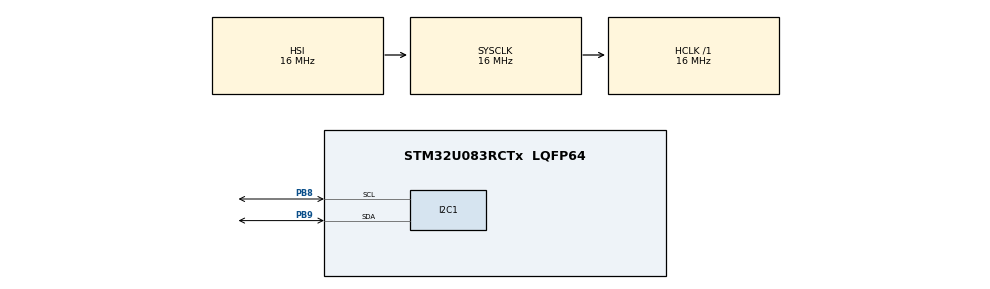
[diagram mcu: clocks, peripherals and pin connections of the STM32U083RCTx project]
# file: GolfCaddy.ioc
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I2C1.Timing=0x00303D5B
Mcu.Family=STM32U0
Mcu.Name=STM32U083RCTx
Mcu.Package=LQFP64
NUCLEO-U083RC.BUTTON=1
NUCLEO-U083RC.LD4=true
NUCLEO-U083RC.VCP=true
NVIC.EXTI4_15_IRQn=true\:0\:0\:false\:false\:true\:false\:true\:true
NVIC.PriorityGroup=NVIC_PRIORITYGROUP_2
PA13\ (SWDIO).GPIO_Label=SWDIO
PA13\ (SWDIO).Signal=DEBUG_JTMS-SWDIO
PA14\ (SWCLK).GPIO_Label=SWCLK
PA14\ (SWCLK).Signal=DEBUG_JTCK-SWCLK
PA2.Signal=USART2_TX
PA3.Signal=USART2_RX
PB8.Mode=I2C
PB8.Signal=I2C1_SCL
PB9.Mode=I2C
PB9.Signal=I2C1_SDA
PC14-OSC32_IN.GPIO_Label=OSC32_IN
PC14-OSC32_IN.Signal=RCC_OSC32_IN
PC15-OSC32_OUT.GPIO_Label=OSC32_OUT
PC15-OSC32_OUT.Signal=RCC_OSC32_OUT
PF0-OSC_IN.GPIO_Label=OSC_IN
PF0-OSC_IN.Signal=RCC_OSC_IN
PF1-OSC_OUT.GPIO_Label=OSC_OUT
PF1-OSC_OUT.Signal=RCC_OSC_OUT
ProjectManager.HeapSize=0x200
ProjectManager.StackSize=0x400
ProjectManager.TargetToolchain=STM32CubeIDE
RCC.AHBFreq_Value=16000000
RCC.CortexFreq_Value=16000000
RCC.HCLKFreq_Value=16000000
RCC.HSE_VALUE=4000000
RCC.HSI48_VALUE=48000000
RCC.HSI_VALUE=16000000
RCC.LSE_VALUE=32768
RCC.MSI_VALUE=4000000
RCC.SYSCLKFreq_VALUE=16000000
RCC.VCOOutputFreq_Value=64000000
VP_NUCLEO-U083RC_VS_BSP_COMMON.Mode=COMMON
VP_PWR_VS_SECSignals.Mode=Security/Privilege
board=NUCLEO-U083RC

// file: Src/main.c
/* USER CODE BEGIN Header */
/**
  ******************************************************************************
  * @file           : main.c
  * @brief          : Main program body
  ******************************************************************************
  * @attention
  *
  * Copyright (c) 2026 STMicroelectronics.
  * All rights reserved.
  *
  * This software is licensed under terms that can be found in the LICENSE file
  * in the root directory of this software component.
  * If no LICENSE file comes with this software, it is provided AS-IS.
  *
  ******************************************************************************
  */
/* USER CODE END Header */
#include "main.h"
#include "i2c.h"
#include "gpio.h"

/* USER CODE BEGIN Includes */
#include "app.h"
/* USER CODE END Includes */

COM_InitTypeDef BspCOMInit;

void SystemClock_Config(void);

int main(void)
{

  /* MCU Configuration--------------------------------------------------------*/

  /* Reset of all peripherals, Initializes the Flash interface and the Systick. */
  HAL_Init();

  /* Configure the system clock */
  SystemClock_Config();

  /* Initialize all configured peripherals */
  MX_GPIO_Init();
  MX_I2C1_Init();
  /* USER CODE BEGIN 2 */
  App_Init();
  /* USER CODE END 2 */

  /* Initialize leds */
  BSP_LED_Init(LED_GREEN);

  /* Initialize USER push-button, will be used to trigger an interrupt each time it's pressed.*/
  BSP_PB_Init(BUTTON_USER, BUTTON_MODE_EXTI);

  /* Initialize COM1 port (115200, 8 bits (7-bit data + 1 stop bit), no parity */
  BspCOMInit.BaudRate   = 115200;
  BspCOMInit.WordLength = COM_WORDLENGTH_8B;
  BspCOMInit.StopBits   = COM_STOPBITS_1;
  BspCOMInit.Parity     = COM_PARITY_NONE;
  BspCOMInit.HwFlowCtl  = COM_HWCONTROL_NONE;
  if (BSP_COM_Init(COM1, &BspCOMInit) != BSP_ERROR_NONE)
  {
    Error_Handler();
  }

  /* Infinite loop */
  /* USER CODE BEGIN WHILE */
  while (1)
  {
	App_Run(HAL_GetTick());
    /* USER CODE END WHILE */

  }
}

void SystemClock_Config(void)
{
  RCC_OscInitTypeDef RCC_OscInitStruct = {0};
  RCC_ClkInitTypeDef RCC_ClkInitStruct = {0};

  /** Configure the main internal regulator output voltage
  */
  HAL_PWREx_ControlVoltageScaling(PWR_REGULATOR_VOLTAGE_SCALE2);

  /** Initializes the RCC Oscillators according to the specified parameters
  * in the RCC_OscInitTypeDef structure.
  */
  RCC_OscInitStruct.OscillatorType = RCC_OSCILLATORTYPE_HSI;
  RCC_OscInitStruct.HSIState = RCC_HSI_ON;
  RCC_OscInitStruct.HSICalibrationValue = RCC_HSICALIBRATION_DEFAULT;
  RCC_OscInitStruct.PLL.PLLState = RCC_PLL_NONE;
  if (HAL_RCC_OscConfig(&RCC_OscInitStruct) != HAL_OK)
  {
    Error_Handler();
  }

  /** Initializes the CPU, AHB and APB buses clocks
  */
  RCC_ClkInitStruct.ClockType = RCC_CLOCKTYPE_HCLK|RCC_CLOCKTYPE_SYSCLK
                              |RCC_CLOCKTYPE_PCLK1;
  RCC_ClkInitStruct.SYSCLKSource = RCC_SYSCLKSOURCE_HSI;
  RCC_ClkInitStruct.AHBCLKDivider = RCC_SYSCLK_DIV1;
  RCC_ClkInitStruct.APB1CLKDivider = RCC_HCLK_DIV1;

  if (HAL_RCC_ClockConfig(&RCC_ClkInitStruct, FLASH_LATENCY_1) != HAL_OK)
  {
    Error_Handler();
  }
}

void Error_Handler(void)
{
  __disable_irq();
  while (1)
  {
  }
}
